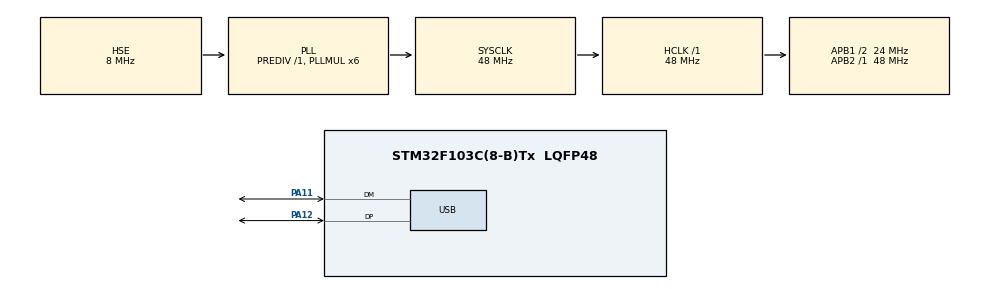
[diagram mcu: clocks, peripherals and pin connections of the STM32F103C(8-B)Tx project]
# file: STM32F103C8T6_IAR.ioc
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Mcu.Family=STM32F1
Mcu.Name=STM32F103C(8-B)Tx
Mcu.Package=LQFP48
NVIC.PriorityGroup=NVIC_PRIORITYGROUP_4
NVIC.USB_LP_CAN1_RX0_IRQn=true\:0\:0\:false\:false\:true\:false\:true\:true
PA11.Mode=Device
PA11.Signal=USB_DM
PA12.Mode=Device
PA12.Signal=USB_DP
PA13.Mode=Serial_Wire
PA13.Signal=SYS_JTMS-SWDIO
PA14.Mode=Serial_Wire
PA14.Signal=SYS_JTCK-SWCLK
PD0-OSC_IN.Mode=HSE-External-Oscillator
PD0-OSC_IN.Signal=RCC_OSC_IN
PD1-OSC_OUT.Mode=HSE-External-Oscillator
PD1-OSC_OUT.Signal=RCC_OSC_OUT
ProjectManager.HeapSize=0x200
ProjectManager.StackSize=0x400
ProjectManager.TargetToolchain=EWARM V8.32
RCC.AHBFreq_Value=48000000
RCC.APB1CLKDivider=RCC_HCLK_DIV2
RCC.APB1Freq_Value=24000000
RCC.APB1TimFreq_Value=48000000
RCC.APB2Freq_Value=48000000
RCC.APB2TimFreq_Value=48000000
RCC.HCLKFreq_Value=48000000
RCC.PLLMUL=RCC_PLL_MUL6
RCC.PLLSourceVirtual=RCC_PLLSOURCE_HSE
RCC.SYSCLKFreq_VALUE=48000000
RCC.SYSCLKSource=RCC_SYSCLKSOURCE_PLLCLK
RCC.USBFreq_Value=48000000
USB_DEVICE.CLASS_NAME_FS=CDC
USB_DEVICE.VirtualMode=Cdc
USB_DEVICE.VirtualModeFS=Cdc_FS
VP_USB_DEVICE_VS_USB_DEVICE_CDC_FS.Mode=CDC_FS
board=custom

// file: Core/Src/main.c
/* USER CODE BEGIN Header */
/**
  ******************************************************************************
  * @file           : main.c
  * @brief          : Main program body
  ******************************************************************************
  * @attention
  *
  * Copyright (c) 2026 STMicroelectronics.
  * All rights reserved.
  *
  * This software is licensed under terms that can be found in the LICENSE file
  * in the root directory of this software component.
  * If no LICENSE file comes with this software, it is provided AS-IS.
  *
  ******************************************************************************
  */
/* USER CODE END Header */
#include "main.h"
#include "usb_device.h"

/* USER CODE BEGIN Includes */
#include "usbd_cdc_if.h"
/* USER CODE END Includes */

void SystemClock_Config(void);
static void MX_GPIO_Init(void);

int main(void)
{

  /* USER CODE BEGIN 1 */
  uint32_t led_t0 = 0U;
  static uint8_t echo_buf[64];   /* static: USB transmits from it asynchronously */
  uint16_t echo_len = 0U;
  /* USER CODE END 1 */

  /* MCU Configuration--------------------------------------------------------*/

  /* Reset of all peripherals, Initializes the Flash interface and the Systick. */
  HAL_Init();

  /* Configure the system clock */
  SystemClock_Config();

  /* USER CODE BEGIN SysInit */
  /* Force USB re-enumeration: BluePill has a fixed D+ pull-up, so the host may
     latch a stale/failed device state across resets. Pulling D+ (PA12) low for
     50 ms makes the host see a disconnect and enumerate afresh. */
  {
    GPIO_InitTypeDef reenum = {0};
    __HAL_RCC_GPIOA_CLK_ENABLE();
    reenum.Pin = GPIO_PIN_12;
    reenum.Mode = GPIO_MODE_OUTPUT_PP;
    reenum.Speed = GPIO_SPEED_FREQ_LOW;
    HAL_GPIO_Init(GPIOA, &reenum);
    HAL_GPIO_WritePin(GPIOA, GPIO_PIN_12, GPIO_PIN_RESET);
    HAL_Delay(50);
    HAL_GPIO_DeInit(GPIOA, GPIO_PIN_12);
  }
  /* USER CODE END SysInit */

  /* Initialize all configured peripherals */
  MX_GPIO_Init();
  MX_USB_DEVICE_Init();

  /* Infinite loop */
  while (1)
  {

    /* USER CODE BEGIN 3 */
    /* Heartbeat LED, 1 Hz, non-blocking (no HAL_Delay - it would stall the echo) */
    if ((HAL_GetTick() - led_t0) >= 500U)
    {
      led_t0 = HAL_GetTick();
      HAL_GPIO_TogglePin(GPIOC, GPIO_PIN_13);
    }

    /* USB CDC echo: fetch a chunk from the RX ring, resend it back.
       If USB TX is busy, keep the chunk and retry on the next loop pass. */
    if (echo_len == 0U)
    {
      echo_len = CDC_ReadRx(echo_buf, sizeof(echo_buf));
    }
    if ((echo_len != 0U) && (CDC_Transmit_FS(echo_buf, echo_len) == USBD_OK))
    {
      echo_len = 0U;
    }
  }
  /* USER CODE END 3 */
}

void SystemClock_Config(void)
{
  RCC_OscInitTypeDef RCC_OscInitStruct = {0};
  RCC_ClkInitTypeDef RCC_ClkInitStruct = {0};
  RCC_PeriphCLKInitTypeDef PeriphClkInit = {0};

  /** Initializes the RCC Oscillators according to the specified parameters
  * in the RCC_OscInitTypeDef structure.
  */
  RCC_OscInitStruct.OscillatorType = RCC_OSCILLATORTYPE_HSE;
  RCC_OscInitStruct.HSEState = RCC_HSE_ON;
  RCC_OscInitStruct.HSEPredivValue = RCC_HSE_PREDIV_DIV1;
  RCC_OscInitStruct.HSIState = RCC_HSI_ON;
  RCC_OscInitStruct.PLL.PLLState = RCC_PLL_ON;
  RCC_OscInitStruct.PLL.PLLSource = RCC_PLLSOURCE_HSE;
  RCC_OscInitStruct.PLL.PLLMUL = RCC_PLL_MUL6;
  if (HAL_RCC_OscConfig(&RCC_OscInitStruct) != HAL_OK)
  {
    Error_Handler();
  }

  /** Initializes the CPU, AHB and APB buses clocks
  */
  RCC_ClkInitStruct.ClockType = RCC_CLOCKTYPE_HCLK|RCC_CLOCKTYPE_SYSCLK
                              |RCC_CLOCKTYPE_PCLK1|RCC_CLOCKTYPE_PCLK2;
  RCC_ClkInitStruct.SYSCLKSource = RCC_SYSCLKSOURCE_PLLCLK;
  RCC_ClkInitStruct.AHBCLKDivider = RCC_SYSCLK_DIV1;
  RCC_ClkInitStruct.APB1CLKDivider = RCC_HCLK_DIV2;
  RCC_ClkInitStruct.APB2CLKDivider = RCC_HCLK_DIV1;

  if (HAL_RCC_ClockConfig(&RCC_ClkInitStruct, FLASH_LATENCY_1) != HAL_OK)
  {
    Error_Handler();
  }
  PeriphClkInit.PeriphClockSelection = RCC_PERIPHCLK_USB;
  PeriphClkInit.UsbClockSelection = RCC_USBCLKSOURCE_PLL;
  if (HAL_RCCEx_PeriphCLKConfig(&PeriphClkInit) != HAL_OK)
  {
    Error_Handler();
  }
}

static void MX_GPIO_Init(void)
{

  /* GPIO Ports Clock Enable */
  __HAL_RCC_GPIOD_CLK_ENABLE();
  __HAL_RCC_GPIOA_CLK_ENABLE();

  /* USER CODE BEGIN MX_GPIO_Init_2 */
  /* On-board LED PC13 (active low) is not configured in the .ioc - set it up
     here so the firmware has a visible "alive" indicator. */
  {
    GPIO_InitTypeDef led = {0};
    __HAL_RCC_GPIOC_CLK_ENABLE();
    HAL_GPIO_WritePin(GPIOC, GPIO_PIN_13, GPIO_PIN_SET); /* LED off */
    led.Pin = GPIO_PIN_13;
    led.Mode = GPIO_MODE_OUTPUT_OD;
    led.Speed = GPIO_SPEED_FREQ_LOW;
    HAL_GPIO_Init(GPIOC, &led);
  }
  /* USER CODE END MX_GPIO_Init_2 */
}

void Error_Handler(void)
{
  __disable_irq();
  while (1)
  {
  }
}
